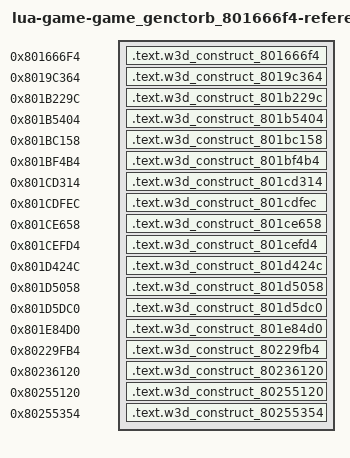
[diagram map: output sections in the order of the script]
/* Generated reference-only placements. All bodies are source-built. */
OUTPUT_FORMAT("elf32-powerpc")
OUTPUT_ARCH(powerpc)
ENTRY(w3d_construct_801666f4)
_SDA_BASE_ = 0x804b2540;
_SDA2_BASE_ = 0x804c2540;
fn_801b4bcc = 0x801b4bcc;
fn_801bbb2c = 0x801bbb2c;
fn_801cb41c = 0x801cb41c;
fn_801cdfec = 0x801cdfec;
fn_801ce3f4 = 0x801ce3f4;
fn_801e81c8 = 0x801e81c8;
fn_801ea0ec = 0x801ea0ec;
fn_80253330 = 0x80253330;
fn_8025d5a8 = 0x8025d5a8;
fn_803426b8 = 0x803426b8;
lbl_803abeb0 = 0x803abeb0;
lbl_803ae6e0 = 0x803ae6e0;
lbl_803aea0c = 0x803aea0c;
lbl_803aece8 = 0x803aece8;
lbl_803aecec = 0x803aecec;
lbl_803c7b24 = 0x803c7b24;
lbl_803c7d84 = 0x803c7d84;
lbl_80411b50 = 0x80411b50;
lbl_80411ba8 = 0x80411ba8;
lbl_804135e0 = 0x804135e0;
lbl_80413628 = 0x80413628;
lbl_80414320 = 0x80414320;
lbl_80414378 = 0x80414378;
lbl_80414528 = 0x80414528;
lbl_80414f88 = 0x80414f88;
lbl_80415348 = 0x80415348;
lbl_80415d80 = 0x80415d80;
lbl_80415e48 = 0x80415e48;
lbl_80415ec0 = 0x80415ec0;
lbl_80415f88 = 0x80415f88;
lbl_80416570 = 0x80416570;
lbl_804165a8 = 0x804165a8;
lbl_80416640 = 0x80416640;
lbl_80416678 = 0x80416678;
lbl_80416760 = 0x80416760;
lbl_804167a8 = 0x804167a8;
lbl_80417010 = 0x80417010;
lbl_8041a0a0 = 0x8041a0a0;
lbl_8041a888 = 0x8041a888;
lbl_8041ba40 = 0x8041ba40;
lbl_8041ba68 = 0x8041ba68;
SECTIONS {
  .text.w3d_construct_801666f4 0x801666f4 : { *(.text.w3d_construct_801666f4) }
  .text.w3d_construct_8019c364 0x8019c364 : { *(.text.w3d_construct_8019c364) }
  .text.w3d_construct_801b229c 0x801b229c : { *(.text.w3d_construct_801b229c) }
  .text.w3d_construct_801b5404 0x801b5404 : { *(.text.w3d_construct_801b5404) }
  .text.w3d_construct_801bc158 0x801bc158 : { *(.text.w3d_construct_801bc158) }
  .text.w3d_construct_801bf4b4 0x801bf4b4 : { *(.text.w3d_construct_801bf4b4) }
  .text.w3d_construct_801cd314 0x801cd314 : { *(.text.w3d_construct_801cd314) }
  .text.w3d_construct_801cdfec 0x801cdfec : { *(.text.w3d_construct_801cdfec) }
  .text.w3d_construct_801ce658 0x801ce658 : { *(.text.w3d_construct_801ce658) }
  .text.w3d_construct_801cefd4 0x801cefd4 : { *(.text.w3d_construct_801cefd4) }
  .text.w3d_construct_801d424c 0x801d424c : { *(.text.w3d_construct_801d424c) }
  .text.w3d_construct_801d5058 0x801d5058 : { *(.text.w3d_construct_801d5058) }
  .text.w3d_construct_801d5dc0 0x801d5dc0 : { *(.text.w3d_construct_801d5dc0) }
  .text.w3d_construct_801e84d0 0x801e84d0 : { *(.text.w3d_construct_801e84d0) }
  .text.w3d_construct_80229fb4 0x80229fb4 : { *(.text.w3d_construct_80229fb4) }
  .text.w3d_construct_80236120 0x80236120 : { *(.text.w3d_construct_80236120) }
  .text.w3d_construct_80255120 0x80255120 : { *(.text.w3d_construct_80255120) }
  .text.w3d_construct_80255354 0x80255354 : { *(.text.w3d_construct_80255354) }
  /DISCARD/ : { *(.text*) *(.rodata*) *(.data*) *(.bss*) *(.sdata*) *(.sbss*) *(.comment) }
}
